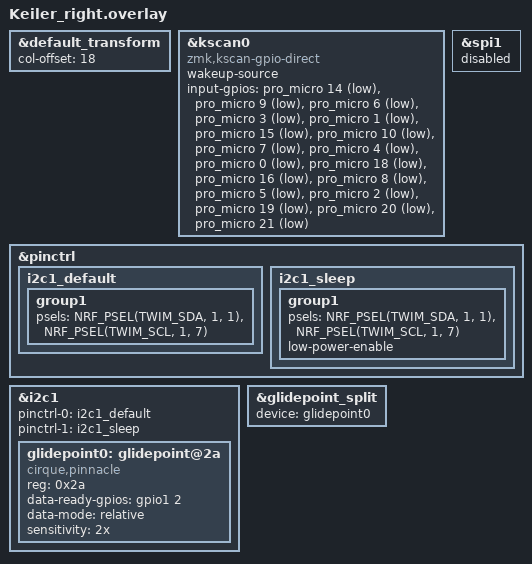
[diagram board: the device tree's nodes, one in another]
#include "Keiler.dtsi"

&default_transform {
	col-offset = <18>;
};

&kscan0 {
    compatible = "zmk,kscan-gpio-direct";
    wakeup-source;
    input-gpios
    = <&pro_micro 14 (GPIO_ACTIVE_LOW | GPIO_PULL_UP)>
    , <&pro_micro  9 (GPIO_ACTIVE_LOW | GPIO_PULL_UP)>
    , <&pro_micro  6 (GPIO_ACTIVE_LOW | GPIO_PULL_UP)>
    , <&pro_micro  3 (GPIO_ACTIVE_LOW | GPIO_PULL_UP)>
    , <&pro_micro  1 (GPIO_ACTIVE_LOW | GPIO_PULL_UP)>
    , <&pro_micro 15 (GPIO_ACTIVE_LOW | GPIO_PULL_UP)>
    , <&pro_micro 10 (GPIO_ACTIVE_LOW | GPIO_PULL_UP)>
    , <&pro_micro  7 (GPIO_ACTIVE_LOW | GPIO_PULL_UP)>
    , <&pro_micro  4 (GPIO_ACTIVE_LOW | GPIO_PULL_UP)>
    , <&pro_micro  0 (GPIO_ACTIVE_LOW | GPIO_PULL_UP)>
    , <&pro_micro 18 (GPIO_ACTIVE_LOW | GPIO_PULL_UP)>
    , <&pro_micro 16 (GPIO_ACTIVE_LOW | GPIO_PULL_UP)>
    , <&pro_micro  8 (GPIO_ACTIVE_LOW | GPIO_PULL_UP)>
    , <&pro_micro  5 (GPIO_ACTIVE_LOW | GPIO_PULL_UP)>
    , <&pro_micro  2 (GPIO_ACTIVE_LOW | GPIO_PULL_UP)>
    , <&pro_micro 19 (GPIO_ACTIVE_LOW | GPIO_PULL_UP)>
    , <&pro_micro 20 (GPIO_ACTIVE_LOW | GPIO_PULL_UP)>
    , <&pro_micro 21 (GPIO_ACTIVE_LOW | GPIO_PULL_UP)>
    ;
};

&spi1 {
    status = "disabled";
};

&pinctrl {
    i2c1_default: i2c1_default {
        group1 {
            psels = <NRF_PSEL(TWIM_SDA, 1, 1)>,
                    <NRF_PSEL(TWIM_SCL, 1, 7)>;
        };
    };

    i2c1_sleep: i2c1_sleep {
        group1 {
            psels = <NRF_PSEL(TWIM_SDA, 1, 1)>,
                    <NRF_PSEL(TWIM_SCL, 1, 7)>;
            low-power-enable;
        };
    };
};

&i2c1 {
    status = "okay";
    pinctrl-0 = <&i2c1_default>;
    pinctrl-1 = <&i2c1_sleep>;
    pinctrl-names = "default", "sleep";

    glidepoint0: glidepoint@2a {
        compatible = "cirque,pinnacle";
        reg = <0x2a>;
        status = "okay";
        data-ready-gpios = <&gpio1 2 GPIO_ACTIVE_HIGH>;

        data-mode = "relative";
        sensitivity = "2x";
    };
};

&glidepoint_split {
    device = <&glidepoint0>;
};
